AUTOSAR XML (schema 4-2-2)
package /ComponentTypes
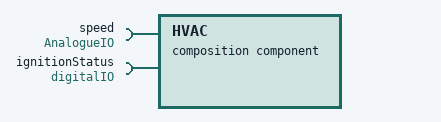
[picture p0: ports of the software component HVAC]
  composition sw component type HVAC
    require port speed: required-interface=AnalogueIO
    require port ignitionStatus: required-interface=digitalIO
    29 x component:
      SAFace: type=Switch
      SAFoot: type=Switch
      SAWindow: type=Switch
      SAHeatedDriverSeats: type=HeatedSeats
      SAHeatedPassengerSeats: type=HeatedSeats
      SAHotColdDriver: type=AirMixOut
      SAHotColdPassenger: type=AirMixOut
      SAFaceFoot: type=AirMixOut
      SAFaceVent: type=AirMixOut
      SABlowerMotorSpeed: type=AirBlowOut
      SAPassengerCurrentTempSet: type=CabinTempClosedLoop
      ECU: type=ECU
      SAOutsideTemp: type=Temp
      SADriverCabinTempSet: type=CabinTempClosedLoop
      SAAirBlower: type=AirBlow
      SAOutsideTempOutside: type=TempOut
      SADriverCabinTempOut: type=TempOut
      SAHeatedDriverSeatsOut: type=HeatedSeatsOut
      SAHeatedPassengerSeatOut: type=HeatedSeatsOut
      SADriverCabinTemp: type=Temp
      SAPassengerCabinTemp: type=Temp
      faceDir: type=SwitchOut
      windowDir: type=SwitchOut
      footDir: type=SwitchOut
      HotColdDriver: type=AirMixIn
      HotColdPassenger: type=AirMixIn
      FaceFoot: type=AirMixIn
      FaceVent: type=AirMixIn
      SAPassengerCabinTempOut: type=TempOut
    delegate ECU.ignition <-> outer port ignitionStatus
    delegate ECU.speed <-> outer port speed
    connect SAOutsideTemp.temp -> ECU.outsideTemp
    connect ECU.tempOutside -> SAOutsideTempOutside.temp
    connect SAPassengerCabinTemp.temp -> ECU.PassengerTemp
    connect SADriverCabinTemp.temp -> ECU.driverTemp
    connect SAFoot.DialSet -> ECU.footSet
    connect SAWindow.DialSet -> ECU.windowSet
    connect SAHeatedDriverSeats.heatedSeatsOnOff -> ECU.heatedDriverSeatsOnOff
    connect SAFace.DialSet -> ECU.faceSet
    connect SAHeatedPassengerSeats.heatedSeatsOnOff -> ECU.heatedPassengerSeatsOnOff
    connect SAAirBlower.PWMBlowerMotorSpeed -> ECU.PWMAirBlowIn
    connect ECU.hotColdDriver -> SAHotColdDriver.InputPercentageStepper
    connect ECU.FaceFoot -> SAFaceFoot.InputPercentageStepper
    connect ECU.HotColdPassenger -> SAHotColdPassenger.InputPercentageStepper
    connect ECU.FaceVent -> SAFaceVent.InputPercentageStepper
    connect ECU.cabinDriverTemp -> SADriverCabinTempOut.temp
    connect ECU.PWMAirBlowOutput -> SABlowerMotorSpeed.pwmBlowerSpeedOut
    connect ECU.DriverSeatsOnOff -> SAHeatedDriverSeatsOut.heatedSeatsOnOff
    connect ECU.PassengerSeatsOnOff -> SAHeatedPassengerSeatOut.heatedSeatsOnOff
    connect ECU.faceDir -> faceDir.switchIn
    connect ECU.WindowDir -> windowDir.switchIn
    connect ECU.footDir -> footDir.switchIn
    connect HotColdDriver.FlapSettingPercent -> ECU.HotColdDriverIn
    connect HotColdPassenger.FlapSettingPercent -> ECU.HotColdPassengerIn
    connect FaceVent.FlapSettingPercent -> ECU.FaceVentIn
    connect FaceFoot.FlapSettingPercent -> ECU.FaceFootIn
    connect ECU.cabinPassengerTemp -> SAPassengerCabinTempOut.temp
    connect ECU.currentPassengerTempSet -> SAPassengerCurrentTempSet.currentTempSet
    connect ECU.currentDriverTempSet -> SADriverCabinTempSet.currentTempSet
